AUTOSAR XML (schema 00051)
standard types defined: boolean, float64, uint16, uint32
package /Components
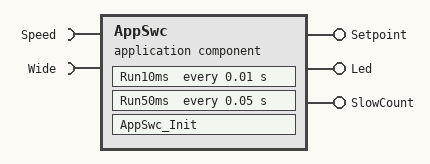
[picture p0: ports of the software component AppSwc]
  application sw component type AppSwc
    require port Speed: nonqueued-receiver-com-spec{data-element=Speed, init-value=0}, required-interface=Speed
    require port Wide: nonqueued-receiver-com-spec{data-element=Wide, init-value=0}, required-interface=Wide
    provide port Setpoint: nonqueued-sender-com-spec{data-element=Setpoint, init-value=0}, provided-interface=Setpoint
    provide port Led: nonqueued-sender-com-spec{data-element=Led, init-value=0}, provided-interface=Led
    provide port SlowCount: nonqueued-sender-com-spec{data-element=SlowCount, init-value=0}, provided-interface=SlowCount
    behavior AppSwc_IB
      timing event Event_Run10ms: start-on-event=Run10ms, period=0.01
      timing event Event_Run50ms: start-on-event=Run50ms, period=0.05
      runnable AppSwc_Init
        data-send-points:
          access OUT_Setpoint_Setpoint: accessed-variable=Setpoint.Setpoint
      runnable Run10ms
        data-receive-point-by-arguments:
          access IN_Speed_Speed: accessed-variable=Speed.Speed
          access IN_Wide_Wide: accessed-variable=Wide.Wide
        data-send-points:
          access OUT_Setpoint_Setpoint: accessed-variable=Setpoint.Setpoint
          access OUT_Led_Led: accessed-variable=Led.Led
      runnable Run50ms
        data-receive-point-by-arguments:
          access IN_Speed_Speed: accessed-variable=Speed.Speed
        data-send-points:
          access OUT_SlowCount_SlowCount: accessed-variable=SlowCount.SlowCount
package /Interfaces
  5 x sender receiver interface:
    Speed
      data Speed: type=uint32
    Wide
      data Wide: type=float64
    Setpoint
      data Setpoint: type=uint16
    Led
      data Led: type=boolean
    SlowCount
      data SlowCount: type=uint32
